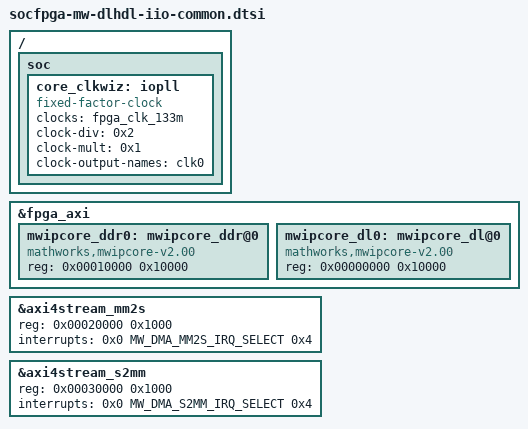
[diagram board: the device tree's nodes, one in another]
/{ 
	soc { 
		core_clkwiz: iopll { 
			compatible = "fixed-factor-clock";
			clocks = <&fpga_clk_133m>;
			#clock-cells = <0x1>;
			clock-div = <0x2>;
			clock-mult = <0x1>;
			clock-output-names = "clk0";
 		}; 
}; 
};

&fpga_axi {
		mwipcore_ddr0: mwipcore_ddr@0 {
			compatible = "mathworks,mwipcore-v2.00";
			reg = <0x00010000 0x10000>;
		};
};

&fpga_axi {
		mwipcore_dl0: mwipcore_dl@0 {
			compatible = "mathworks,mwipcore-v2.00";
			reg = <0x00000000 0x10000>;
		};
};

#include "mw-axistream-iio-common.h"
#include "adi-mw-axistream-dma.h"

#undef MW_MM2S_DATAFMT
#undef MW_S2MM_DATAFMT
#undef ADI_MM2S_AXIM_DATAWIDTH
#undef ADI_MM2S_AXIS_DATAWIDTH
#undef ADI_S2MM_AXIS_DATAWIDTH
#undef ADI_S2MM_AXIM_DATAWIDTH

#define MW_MM2S_DATAFMT "u32/32>>0"
#define MW_S2MM_DATAFMT "u32/32>>0"

#define ADI_MM2S_AXIM_DATAWIDTH <0x40>
#define ADI_MM2S_AXIS_DATAWIDTH <0x20>
#define ADI_S2MM_AXIS_DATAWIDTH <0x20>
#define ADI_S2MM_AXIM_DATAWIDTH <0x40>

#include "socfpga-mw-cma.dtsi" 
#include "adi-mw-dlhdl-iio-common.dtsi" 
&axi4stream_mm2s { 
 	reg = <0x00020000 0x1000>; 
	interrupts = <0x0 MW_DMA_MM2S_IRQ_SELECT 0x4>;
}; 

 
&axi4stream_s2mm { 
 	reg = <0x00030000 0x1000>; 
	interrupts = <0x0 MW_DMA_S2MM_IRQ_SELECT 0x4>;
}; 

/delete-node/ &mwipcore0;
